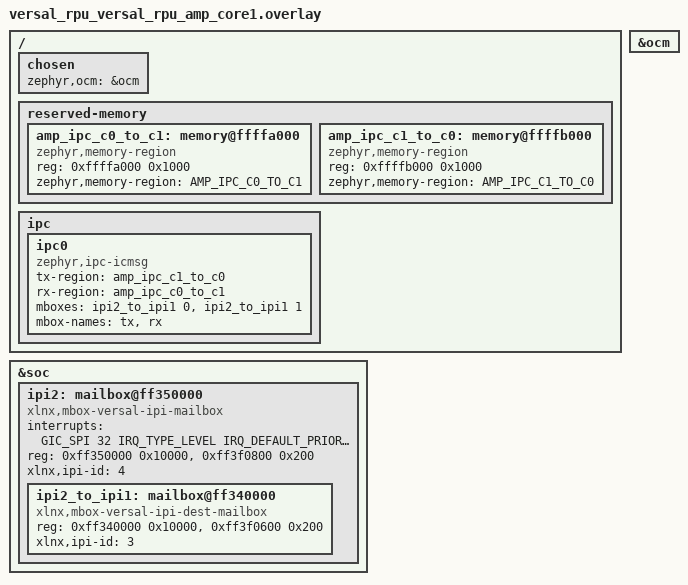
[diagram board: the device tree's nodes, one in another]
/*
 * Copyright (c) 2026 Advanced Micro Devices, Inc.
 *
 * SPDX-License-Identifier: Apache-2.0
 *
 * IPC service (ICMSG) on Versal RPU AMP core 1: swap tx/rx vs core 0.
 *
 * IPI layout matches samples/boards/amd/amp_ipi_exchange (core 1 overlay).
 */

#include <zephyr/dt-bindings/interrupt-controller/arm-gic.h>

/ {
	chosen {
		zephyr,ocm = &ocm;
	};

	reserved-memory {
		#address-cells = <1>;
		#size-cells = <1>;

		amp_ipc_c0_to_c1: memory@ffffa000 {
			compatible = "zephyr,memory-region";
			reg = <0xffffa000 0x1000>;
			zephyr,memory-region = "AMP_IPC_C0_TO_C1";
		};

		amp_ipc_c1_to_c0: memory@ffffb000 {
			compatible = "zephyr,memory-region";
			reg = <0xffffb000 0x1000>;
			zephyr,memory-region = "AMP_IPC_C1_TO_C0";
		};
	};

	ipc {
		ipc0: ipc0 {
			compatible = "zephyr,ipc-icmsg";
			status = "okay";
			tx-region = <&amp_ipc_c1_to_c0>;
			rx-region = <&amp_ipc_c0_to_c1>;
			mboxes = <&ipi2_to_ipi1 0>, <&ipi2_to_ipi1 1>;
			mbox-names = "tx", "rx";
		};
	};
};

&ocm {
	status = "okay";
};

&soc {
	ipi2: mailbox@ff350000 {
		compatible = "xlnx,mbox-versal-ipi-mailbox";
		status = "okay";
		interrupts = <GIC_SPI 32 IRQ_TYPE_LEVEL IRQ_DEFAULT_PRIORITY>;
		reg = <0xff350000 0x10000>, <0xff3f0800 0x200>;
		reg-names = "ctrl", "msg";
		xlnx,ipi-id = <4>;
		#address-cells = <1>;
		#size-cells = <1>;

		ipi2_to_ipi1: mailbox@ff340000 {
			compatible = "xlnx,mbox-versal-ipi-dest-mailbox";
			reg = <0xff340000 0x10000>, <0xff3f0600 0x200>;
			reg-names = "ctrl", "msg";
			xlnx,ipi-id = <3>;
			#mbox-cells = <1>;
		};
	};
};
